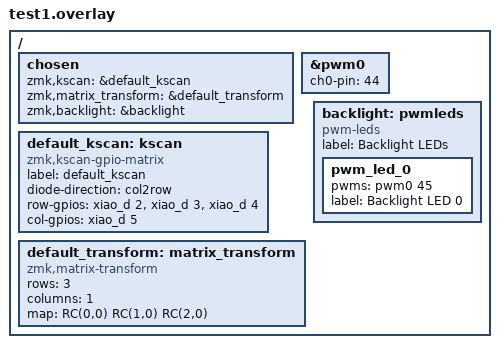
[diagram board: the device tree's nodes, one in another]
#include <dt-bindings/zmk/bt.h>
#include <dt-bindings/zmk/matrix_transform.h>
#include <dt-bindings/zmk/outputs.h>

/ {
    chosen {
        zmk,kscan = &default_kscan;
        zmk,matrix_transform = &default_transform;
        zmk,backlight = &backlight;
    };

    &pwm0 {
        status = "okay";
        ch0-pin = <44>;
        /* ch0-inverted; */
    };

    default_kscan: kscan {
        compatible = "zmk,kscan-gpio-matrix";
        label = "default_kscan";
        diode-direction = "col2row";

        row-gpios = <&xiao_d 2 (GPIO_ACTIVE_HIGH | GPIO_PULL_DOWN)>,
                    <&xiao_d 3 (GPIO_ACTIVE_HIGH | GPIO_PULL_DOWN)>,
                    <&xiao_d 4 (GPIO_ACTIVE_HIGH | GPIO_PULL_DOWN)>;

        col-gpios = <&xiao_d 5 GPIO_ACTIVE_HIGH>;
    };

    default_transform: matrix_transform {
        compatible = "zmk,matrix-transform";
        rows = <3>;
        columns = <1>;

        map = <
            RC(0,0)
            RC(1,0)
            RC(2,0)
        >;
    };
};

/ {
    backlight: pwmleds {
        compatible = "pwm-leds";
        label = "Backlight LEDs";
        pwm_led_0 {
            pwms = <&pwm0 45>;
            label = "Backlight LED 0";
        };
    };
};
